AUTOSAR XML (schema 4-2-1)
package /COM/VECTOR/CFG/WORKFLOW/SYSDESC/SYNC
  system SYSTEM
    system mapping MAPPINGS
    root-software-compositions:
      root sw composition prototype COMPOSITIONTYPE: flat-map=FLATMAP, software-composition=COMPOSITIONTYPE
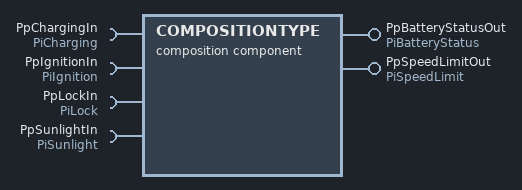
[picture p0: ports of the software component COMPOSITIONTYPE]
  composition sw component type COMPOSITIONTYPE
    provide port PpBatteryStatusOut: nonqueued-sender-com-spec=data-element=DeBatteryStatus, provided-interface=PiBatteryStatus
    provide port PpSpeedLimitOut: nonqueued-sender-com-spec=data-element=DeSpeedLimit, provided-interface=PiSpeedLimit
    4 x require port:
      PpChargingIn: nonqueued-receiver-com-spec{data-element=DeCharging, filter=data-filter-type=ALWAYS}, required-interface=PiCharging
      PpIgnitionIn: nonqueued-receiver-com-spec{data-element=DeIgnition, filter=data-filter-type=ALWAYS}, required-interface=PiIgnition
      PpLockIn: nonqueued-receiver-com-spec{data-element=DeLock, filter=data-filter-type=ALWAYS}, required-interface=PiLock
      PpSunlightIn: nonqueued-receiver-com-spec{data-element=DeSunlight, filter=data-filter-type=ALWAYS}, required-interface=PiSunlight
    16 x component:
      Dem: type=Dem
      Det: type=Det
      EcuM: type=EcuM
      NvM: type=NvM
      ComM: type=ComM
      BswM: type=BswM
      Dcm: type=Dcm
      CtSaBatteryManagement: type=CtSaBatteryManagement
      CtIoHwAb: type=CtIoHwAb
      CpSaSunlightPresence: type=CtSaSunlightPresence
      CpSaSpeedLimit: type=CtSaSpeedLimit
      CpSaSolarPanelControl: type=CtSaSolarPanelControl
      CpSaLockControl: type=CtSaLockControl
      CpSaEngineControl: type=CtSaEngineControl
      CpApSEVMIController: type=CtApSEVMIController
      CtSaBatteryModeManager: type=CtSaBatteryModeManager
    connect BswM.Switch_ESH_ModeSwitch -> BswM.Notification_ESH_ModeNotification
    connect CpSaEngineControl.PpIgnition -> CpApSEVMIController.PpIgnition
    connect CpSaLockControl.PpLock -> CpApSEVMIController.PpLock
    connect CpSaSolarPanelControl.PpCharging -> CpApSEVMIController.PpCharging
    connect CpSaSunlightPresence.PpSunlight -> CpApSEVMIController.PpSunlight
    connect CpApSEVMIController.PpSpeedLimit -> CpSaSpeedLimit.PpSpeedLimit
    connect CpApSEVMIController.PpBatteryStatus -> CtSaBatteryManagement.PpBatteryStatus
    connect CtIoHwAb.PpSpeed -> CpApSEVMIController.PpSpeed
    delegate CpSaSpeedLimit.PpSpeedLimitOut <-> outer port PpSpeedLimitOut
    delegate CtSaBatteryManagement.PpBatteryStatusOut <-> outer port PpBatteryStatusOut
    delegate CpSaSunlightPresence.PpSunlightIn <-> outer port PpSunlightIn
    delegate CpSaLockControl.PpLockIn <-> outer port PpLockIn
    delegate CpSaEngineControl.PpIgnitionIn <-> outer port PpIgnitionIn
    delegate CpSaSolarPanelControl.PpChargingIn <-> outer port PpChargingIn
    connect ComM.UR_USR_CHNL_CAN00 -> CpApSEVMIController.PpComMUserRequestCtApSEVMIController
    connect ComM.UM_USR_CHNL_CAN00 -> CpApSEVMIController.PpComMCurrentModeSEVMIController
  end to end protection set E2EPROTECTIONSET
  port interface mapping set PORTINTERFACEMAPPINGSET
